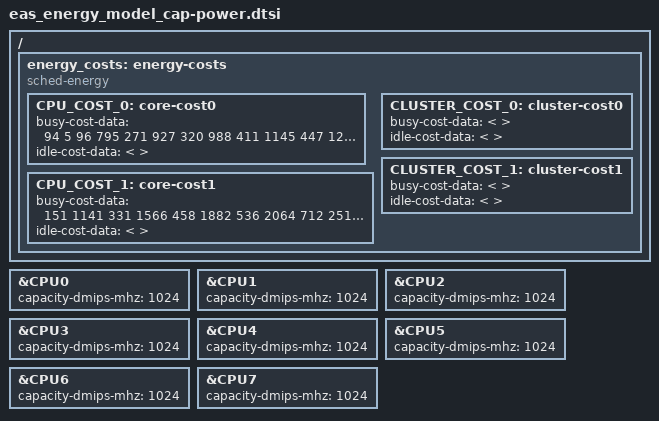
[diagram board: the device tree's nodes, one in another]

&CPU0 {
	capacity-dmips-mhz = <1024>;
};

&CPU1 {
	capacity-dmips-mhz = <1024>;
};

&CPU2 {
	capacity-dmips-mhz = <1024>;
};

&CPU3 {
	capacity-dmips-mhz = <1024>;
};

&CPU4 {
	capacity-dmips-mhz = <1024>;
};

&CPU5 {
	capacity-dmips-mhz = <1024>;
};

&CPU6 {
	capacity-dmips-mhz = <1024>;
};

&CPU7 {
	capacity-dmips-mhz = <1024>;
};

/ {
	energy_costs: energy-costs {
		compatible = "sched-energy";

		CPU_COST_0: core-cost0 {
			busy-cost-data = <
				  94    5
				  96  795
				 271  927
				 320  988
				 411 1145
				 447 1226
				 507 1403
				 568 1648
			>;
			idle-cost-data = <
				
			>;
		};

		CPU_COST_1: core-cost1 {
			busy-cost-data = <
				 151 1141
				 331 1566
				 458 1882
				 536 2064
				 712 2511
				 780 2687
				 917 2994
				1024 3391
			>;
			idle-cost-data = <
				
			>;
		};

		CLUSTER_COST_0: cluster-cost0 {
			busy-cost-data = <
			>;
			idle-cost-data = <
				
			>;
		};

		CLUSTER_COST_1: cluster-cost1 {
			busy-cost-data = <
			>;
			idle-cost-data = <
				
			>;
		};
	}; /* energy-costs */
};
